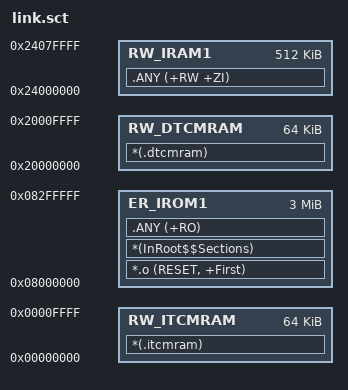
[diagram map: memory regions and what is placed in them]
; *************************************************************
; *** Scatter-Loading Description File generated by uVision ***
; *************************************************************

LR_IROM1 0x08000000 0x00300000  {    ; load region size_region (3MB Flash)
  ER_IROM1 0x08000000 0x00300000  {  ; load address = execution address
   *.o (RESET, +First)
   *(InRoot$$Sections)
   .ANY (+RO)
  }
  RW_ITCMRAM 0x00000000 0x00010000  {  ; ITCM RAM (64KB)
   *(.itcmram)
  }
  RW_DTCMRAM 0x20000000 0x00010000  {  ; DTCM RAM (64KB)
   *(.dtcmram)
  }
  RW_IRAM1 0x24000000 0x00080000  {  ; AXI SRAM - DMA accessible (512KB)
   .ANY (+RW +ZI)
  }
}

